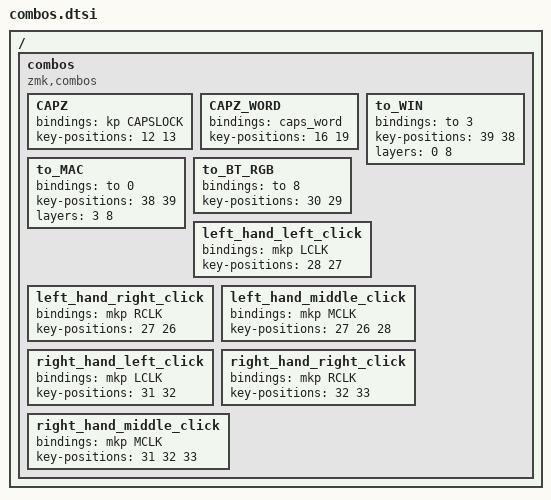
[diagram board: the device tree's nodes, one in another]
/* --- KEY ID LAYOUT --- */
// ╭──────┬──────┬──────┬──────┬──────┬──────╮  ╭──────┬──────┬──────┬──────┬──────┬──────╮
//    00     01     02     03    04      05        06     07     08     09     10     11
// ├──────┼──────┼──────┼──────┼──────┼──────┤  ├──────┼──────┼──────┼──────┼──────┼──────┤
//    12     13     14     15    16      17        18     19     20     21     22     23
// ├──────┼──────┼──────┼──────┼──────┼──────┤  ├──────┼──────┼──────┼──────┼──────┼──────┤
//    24     25     26     27    28      29        30     31     32     33     34     35
// ╰──────┴──────┴──────┼──────┼──────┼──────┤  ├──────┼──────┼──────┴──────┴──────┴──────╯
//                         36     37     38        39     40     41
//                      ╰──────┴──────┴──────╯  ╰──────┴──────┴──────╯

/ {
    combos {
        compatible = "zmk,combos";

        CAPZ {
            bindings = <&kp CAPSLOCK>;
            key-positions = <12 13>;
        };

        CAPZ_WORD {
            bindings = <&caps_word>;
            key-positions = <16 19>;
        };

        to_WIN {
            bindings = <&to 3>;
            key-positions = <39 38>;
            layers = <0 8>;
        };

        to_MAC {
            bindings = <&to 0>;
            key-positions = <38 39>;
            layers = <3 8>;
        };

        to_BT_RGB {
            bindings = <&to 8>;
            key-positions = <30 29>;
        };

        left_hand_left_click {
            bindings = <&mkp LCLK>;
            key-positions = <28 27>;
        };

        left_hand_right_click {
            bindings = <&mkp RCLK>;
            key-positions = <27 26>;
        };

        left_hand_middle_click {
            bindings = <&mkp MCLK>;
            key-positions = <27 26 28>;
        };

        right_hand_left_click {
            bindings = <&mkp LCLK>;
            key-positions = <31 32>;
        };

        right_hand_right_click {
            bindings = <&mkp RCLK>;
            key-positions = <32 33>;
        };

        right_hand_middle_click {
            bindings = <&mkp MCLK>;
            key-positions = <31 32 33>;
        };
    };
};
